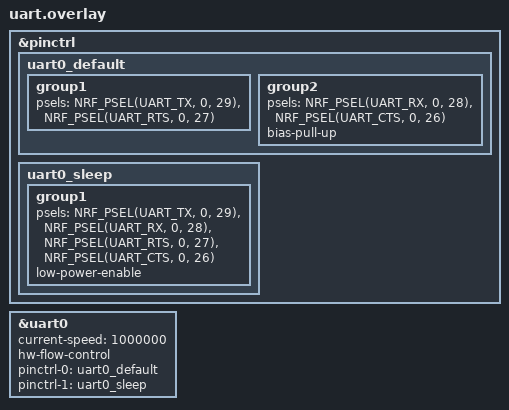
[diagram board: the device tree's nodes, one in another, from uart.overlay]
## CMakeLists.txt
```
cmake_minimum_required(VERSION 3.20.0)

list(APPEND DTC_OVERLAY_FILE "${CMAKE_SOURCE_DIR}/uart.overlay")

find_package(Zephyr REQUIRED HINTS $ENV{ZEPHYR_BASE})
project(ipc_dfu_helper VERSION 1.0.0)

target_sources(app PRIVATE src/main.c)
```

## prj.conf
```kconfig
#
# Copyright (c) 2021 Nordic Semiconductor ASA
#
# SPDX-License-Identifier: LicenseRef-Nordic-5-Clause
#

CONFIG_LOG=y
CONFIG_LOG_BACKEND_RTT=y
CONFIG_LOG_BACKEND_UART=n
CONFIG_UART_CONSOLE=n
CONFIG_USE_SEGGER_RTT=y
CONFIG_RTT_CONSOLE=y

# Enable FPU
CONFIG_FPU=y

# Enable mcumgr.
CONFIG_MCUMGR=y
CONFIG_ZCBOR=y
CONFIG_FLASH=y
CONFIG_FLASH_MAP=y
CONFIG_STREAM_FLASH=y
CONFIG_IMG_MANAGER=y
CONFIG_MCUBOOT_BOOTUTIL_LIB=y

# Some command handlers require a large stack.
CONFIG_SYSTEM_WORKQUEUE_STACK_SIZE=4096

# nrf_modem requires a larger main stack than is default
CONFIG_MAIN_STACK_SIZE=2048

# Enable the UART mcumgr transports.
CONFIG_MCUMGR_TRANSPORT_UART=y
CONFIG_BASE64=y
CONFIG_CRC=y
CONFIG_UART_MCUMGR_RX_BUF_SIZE=512
CONFIG_MCUMGR_TRANSPORT_NETBUF_SIZE=512

# Required by the `taskstat` command.
CONFIG_THREAD_MONITOR=y

# Enable statistics and statistic names.
CONFIG_STATS=y
CONFIG_STATS_NAMES=y

# Enable STAT and OS from the core commands
CONFIG_MGMT_FMFU=y
CONFIG_MCUMGR_GRP_OS=y
CONFIG_MCUMGR_GRP_STAT=y
CONFIG_MCUMGR_GRP_IMG=y

CONFIG_NRF_MODEM_LIB=y

# Used for getting the modem version
CONFIG_MODEM_INFO=y

CONFIG_NETWORKING=y
CONFIG_NET_SOCKETS=y
CONFIG_NET_SOCKETS_OFFLOAD=y
CONFIG_HEAP_MEM_POOL_SIZE=8192

# Enable MCUBOOT
CONFIG_BOOTLOADER_MCUBOOT=y
```

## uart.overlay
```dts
/*
 * ipc_dfu_helper UART overlay — nRF9160DK v0.14.0
 *
 * Actual RP2040 → nRF91 wiring:
 *   GPIO9  ← P0.29  UART_TX  (nRF91 TX  → RP2040 RX)
 *   GPIO10 → P0.28  UART_RX  (RP2040 TX → nRF91 RX)
 *   GPIO11 ← P0.27  UART_RTS (nRF91 RTS output → RP2040 CTS input)
 *   GPIO12 → P0.26  UART_CTS (nRF91 CTS input  ← RP2040 RTS output)
 *
 * HW flow control enabled: nRF91 asserts RTS when its DMA RX buffer
 * is filling; RP2040 (hw_flow=on) stops sending until RTS is released.
 * RP2040 holds its RTS (GPIO12) LOW = CTS asserted so nRF91 can always TX.
 */

 /delete-node/ &uart0_default;
 /delete-node/ &uart0_sleep;

 &pinctrl {
     uart0_default: uart0_default {
         group1 {
             psels = <NRF_PSEL(UART_TX,  0, 29)>,
                     <NRF_PSEL(UART_RTS, 0, 27)>;
         };
         group2 {
             psels = <NRF_PSEL(UART_RX,  0, 28)>,
                     <NRF_PSEL(UART_CTS, 0, 26)>;
             bias-pull-up;
         };
     };

     uart0_sleep: uart0_sleep {
         group1 {
             psels = <NRF_PSEL(UART_TX,  0, 29)>,
                     <NRF_PSEL(UART_RX,  0, 28)>,
                     <NRF_PSEL(UART_RTS, 0, 27)>,
                     <NRF_PSEL(UART_CTS, 0, 26)>;
             low-power-enable;
         };
     };
 };

 &uart0 {
     status = "okay";
     current-speed = <1000000>;
     hw-flow-control;
     pinctrl-0 = <&uart0_default>;
     pinctrl-1 = <&uart0_sleep>;
     pinctrl-names = "default", "sleep";
 };
```

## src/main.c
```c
/*
 * Adapted from Nordic fmfu_smp_svr sample.
 * Stage1 uses a fixed 6s boot wait — no banner or RTT signalling needed.
 * UART0 carries SMP frames only (async mcumgr transport).
 */

#include <zephyr/kernel.h>
#include <mgmt/fmfu_mgmt.h>
#include <mgmt/fmfu_mgmt_stat.h>
#include <modem/nrf_modem_lib.h>
#include <zephyr/sys/printk.h>
#include <string.h>
#include <modem/modem_info.h>
#include <zephyr/dfu/mcuboot.h>

int main(void)
{
	int err = nrf_modem_lib_init();

	if (err == 0) {
		char modem_version[MODEM_INFO_MAX_RESPONSE_SIZE];

		err = modem_info_init();
		if (err != 0) {
			printk("Modem info Init error: %d\n\r", err);
		} else {
			modem_info_string_get(MODEM_INFO_FW_VERSION,
					modem_version,
					MODEM_INFO_MAX_RESPONSE_SIZE);
			printk("Starting modem mgmt sample\n\r");
			printk("Modem version: %s\n\r", modem_version);
		}
	}

	/* Shutdown modem to prepare for DFU */
	nrf_modem_lib_shutdown();

	nrf_modem_lib_bootloader_init();

	/* Register SMP Communication stats */
	fmfu_mgmt_stat_init();
	/* Initialize MCUMgr handlers for full modem update */
	err = fmfu_mgmt_init();
	if (err) {
		printk("Error in fmfu init: %d\n\r", err);
	}
	printk("Initialized and ready to receive firmware\n\r");

	return 0;
}
```
